AUTOSAR XML (schema 4-2-1)
package /ComponentTypes
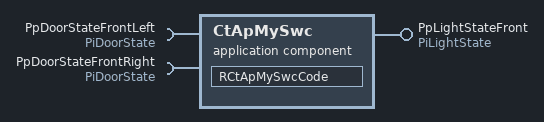
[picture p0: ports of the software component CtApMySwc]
  application sw component type CtApMySwc
    provide port PpLightStateFront: nonqueued-sender-com-spec{data-element=DeLightState, init-value=constant-reference=CLightOff}, provided-interface=PiLightState
    require port PpDoorStateFrontLeft: nonqueued-receiver-com-spec{data-element=DeDoorState, filter=data-filter-type=ALWAYS, init-value=constant-reference=CDoorClosed}, required-interface=PiDoorState
    require port PpDoorStateFrontRight: nonqueued-receiver-com-spec{data-element=DeDoorState, filter=data-filter-type=ALWAYS, init-value=constant-reference=CDoorClosed}, required-interface=PiDoorState
    behavior CtApMySwc_InternalBehavior: data-type-mapping=DemoTypeMapping
      data received event DRT_RCtApMySwcCode_PpDoorStateFrontLeft_DeDoorState: start-on-event=RCtApMySwcCode, data=PpDoorStateFrontLeft.DeDoorState
      data received event DRT_RCtApMySwcCode_PpDoorStateFrontRight_DeDoorState: start-on-event=RCtApMySwcCode, data=PpDoorStateFrontRight.DeDoorState
      runnable RCtApMySwcCode
        data-read-access:
          access REC_PpDoorStateFrontLeft_DeDoorState: accessed-variable=PpDoorStateFrontLeft.DeDoorState
        data-receive-point-by-arguments:
          access REC_PpDoorStateFrontRight_DeDoorState: accessed-variable=PpDoorStateFrontRight.DeDoorState
        data-send-points:
          access SEND_PpLightStateFront_DeLightState: accessed-variable=PpLightStateFront.DeLightState
  swc implementation CtApMySwc_Implementation: behavior=CtApMySwc_InternalBehavior
    code-descriptors:
      code Default: artifact-descriptors=autosar-engineering-object={short-label=Default, category=SWSRC}
